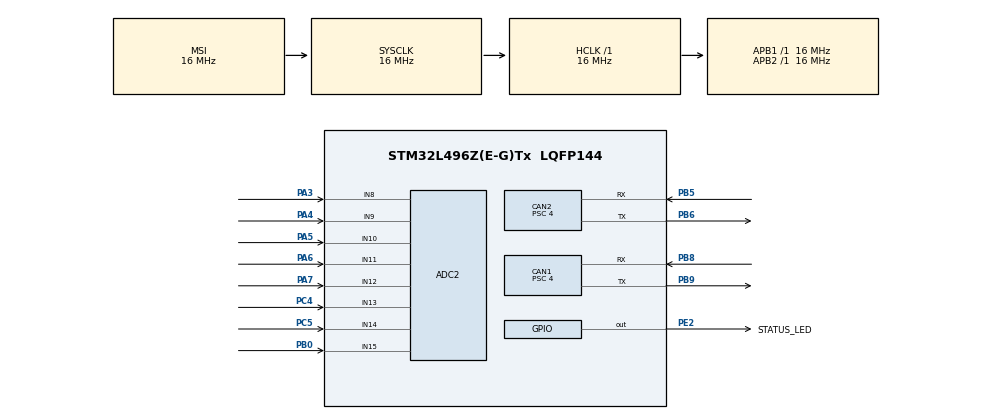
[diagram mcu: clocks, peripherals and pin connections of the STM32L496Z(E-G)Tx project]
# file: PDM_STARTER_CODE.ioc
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ADC2.Channel-1\#ChannelRegularConversion=ADC_CHANNEL_8
ADC2.Channel-2\#ChannelRegularConversion=ADC_CHANNEL_9
ADC2.Channel-3\#ChannelRegularConversion=ADC_CHANNEL_10
ADC2.Channel-4\#ChannelRegularConversion=ADC_CHANNEL_11
ADC2.Channel-5\#ChannelRegularConversion=ADC_CHANNEL_12
ADC2.Channel-6\#ChannelRegularConversion=ADC_CHANNEL_13
ADC2.Channel-7\#ChannelRegularConversion=ADC_CHANNEL_14
ADC2.Channel-8\#ChannelRegularConversion=ADC_CHANNEL_15
ADC2.ClockPrescaler=ADC_CLOCK_ASYNC_DIV1
ADC2.DMAContinuousRequests=ENABLE
ADC2.EOCSelection=ADC_EOC_SEQ_CONV
ADC2.EnableAnalogWatchDog1=false
ADC2.EnableAnalogWatchDog2=false
ADC2.ExternalTrigConv=ADC_EXTERNALTRIG_T8_TRGO
ADC2.NbrOfConversion=8
ADC2.NbrOfConversionFlag=1
ADC2.OffsetNumber-1\#ChannelRegularConversion=ADC_OFFSET_NONE
ADC2.OffsetNumber-2\#ChannelRegularConversion=ADC_OFFSET_NONE
ADC2.OffsetNumber-3\#ChannelRegularConversion=ADC_OFFSET_NONE
ADC2.OffsetNumber-4\#ChannelRegularConversion=ADC_OFFSET_NONE
ADC2.OffsetNumber-5\#ChannelRegularConversion=ADC_OFFSET_NONE
ADC2.OffsetNumber-6\#ChannelRegularConversion=ADC_OFFSET_NONE
ADC2.OffsetNumber-7\#ChannelRegularConversion=ADC_OFFSET_NONE
ADC2.OffsetNumber-8\#ChannelRegularConversion=ADC_OFFSET_NONE
ADC2.Rank-1\#ChannelRegularConversion=1
ADC2.Rank-2\#ChannelRegularConversion=2
ADC2.Rank-3\#ChannelRegularConversion=3
ADC2.Rank-4\#ChannelRegularConversion=4
ADC2.Rank-5\#ChannelRegularConversion=5
ADC2.Rank-6\#ChannelRegularConversion=6
ADC2.Rank-7\#ChannelRegularConversion=7
ADC2.Rank-8\#ChannelRegularConversion=8
ADC2.SamplingTime-1\#ChannelRegularConversion=ADC_SAMPLETIME_12CYCLES_5
ADC2.SamplingTime-2\#ChannelRegularConversion=ADC_SAMPLETIME_12CYCLES_5
ADC2.SamplingTime-3\#ChannelRegularConversion=ADC_SAMPLETIME_12CYCLES_5
ADC2.SamplingTime-4\#ChannelRegularConversion=ADC_SAMPLETIME_12CYCLES_5
ADC2.SamplingTime-5\#ChannelRegularConversion=ADC_SAMPLETIME_12CYCLES_5
ADC2.SamplingTime-6\#ChannelRegularConversion=ADC_SAMPLETIME_12CYCLES_5
ADC2.SamplingTime-7\#ChannelRegularConversion=ADC_SAMPLETIME_12CYCLES_5
ADC2.SamplingTime-8\#ChannelRegularConversion=ADC_SAMPLETIME_12CYCLES_5
CAN1.BS1=CAN_BS1_2TQ
CAN1.CalculateBaudRate=1000000
CAN1.CalculateTimeBit=1000
CAN1.CalculateTimeQuantum=250.0
CAN1.Prescaler=4
CAN2.BS1=CAN_BS1_2TQ
CAN2.CalculateBaudRate=1000000
CAN2.CalculateTimeBit=1000
CAN2.CalculateTimeQuantum=250.0
CAN2.Prescaler=4
Dma.ADC2.0.Direction=DMA_PERIPH_TO_MEMORY
Dma.ADC2.0.Instance=DMA1_Channel2
Dma.ADC2.0.MemDataAlignment=DMA_MDATAALIGN_WORD
Dma.ADC2.0.MemInc=DMA_MINC_ENABLE
Dma.ADC2.0.Mode=DMA_CIRCULAR
Dma.ADC2.0.PeriphDataAlignment=DMA_PDATAALIGN_WORD
Dma.ADC2.0.PeriphInc=DMA_PINC_DISABLE
Dma.ADC2.0.Priority=DMA_PRIORITY_LOW
Dma.Request0=ADC2
FREERTOS.Tasks01=defaultTask,24,128,StartDefaultTask,Default,NULL,Dynamic,NULL,NULL;statusTask,24,128,statusTaskStart,Default,NULL,Dynamic,NULL,NULL;can1Task,24,128,can1TaskStart,As external,NULL,Dynamic,NULL,NULL;can2Task,24,128,can2TaskStart,As external,NULL,Dynamic,NULL,NULL;adcTask,24,128,adcTaskStart,As external,NULL,Dynamic,NULL,NULL
FREERTOS.configENABLE_FPU=0
FREERTOS.configTOTAL_HEAP_SIZE=25360
FREERTOS.configUSE_NEWLIB_REENTRANT=1
Mcu.Family=STM32L4
Mcu.Name=STM32L496Z(E-G)Tx
Mcu.Package=LQFP144
NVIC.DMA1_Channel2_IRQn=true\:5\:0\:false\:false\:true\:true\:false\:true\:true
NVIC.PriorityGroup=NVIC_PRIORITYGROUP_4
NVIC.TIM6_DAC_IRQn=true\:15\:0\:false\:false\:true\:false\:false\:true\:true
NVIC.TimeBase=TIM6_DAC_IRQn
NVIC.TimeBaseIP=TIM6
PA3.Signal=ADCx_IN8
PA4.Signal=ADCx_IN9
PA5.Signal=ADCx_IN10
PA6.Signal=ADCx_IN11
PA7.Signal=ADCx_IN12
PB0.Signal=ADCx_IN15
PB5.Mode=CAN_Activate
PB5.Signal=CAN2_RX
PB6.Mode=CAN_Activate
PB6.Signal=CAN2_TX
PB8.Mode=CAN_Activate
PB8.Signal=CAN1_RX
PB9.Mode=CAN_Activate
PB9.Signal=CAN1_TX
PC4.Signal=ADCx_IN13
PC5.Signal=ADCx_IN14
PC9.Signal=S_TIM3_CH4
PE2.GPIO_Label=STATUS_LED
PE2.Signal=GPIO_Output
ProjectManager.HeapSize=0x200
ProjectManager.StackSize=0x400
ProjectManager.TargetToolchain=STM32CubeIDE
RCC.ADCFreq_Value=64000000
RCC.AHBFreq_Value=16000000
RCC.APB1Freq_Value=16000000
RCC.APB1TimFreq_Value=16000000
RCC.APB2Freq_Value=16000000
RCC.APB2TimFreq_Value=16000000
RCC.CortexFreq_Value=16000000
RCC.HCLKFreq_Value=16000000
RCC.HSE_VALUE=8000000
RCC.HSI48_VALUE=48000000
RCC.HSI_VALUE=16000000
RCC.LSE_VALUE=32768
RCC.MSIClockRange=RCC_MSIRANGE_8
RCC.MSI_VALUE=16000000
RCC.SYSCLKFreq_VALUE=16000000
RCC.USBFreq_Value=64000000
RCC.VCOOutputFreq_Value=128000000
SH.ADCx_IN10.0=ADC2_IN10,IN10-Single-Ended
SH.ADCx_IN11.0=ADC2_IN11,IN11-Single-Ended
SH.ADCx_IN12.0=ADC2_IN12,IN12-Single-Ended
SH.ADCx_IN13.0=ADC2_IN13,IN13-Single-Ended
SH.ADCx_IN14.0=ADC2_IN14,IN14-Single-Ended
SH.ADCx_IN15.0=ADC2_IN15,IN15-Single-Ended
SH.ADCx_IN8.0=ADC2_IN8,IN8-Single-Ended
SH.ADCx_IN9.0=ADC2_IN9,IN9-Single-Ended
SH.S_TIM3_CH4.0=TIM3_CH4
TIM8.Period=49
TIM8.Prescaler=1600-1
TIM8.TIM_MasterOutputTrigger=TIM_TRGO_UPDATE
VP_FREERTOS_VS_CMSIS_V2.Mode=CMSIS_V2
VP_SYS_VS_tim6.Mode=TIM6
VP_TIM8_VS_ClockSourceINT.Mode=Internal
board=custom

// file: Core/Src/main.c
/* USER CODE BEGIN Header */
/**
  ******************************************************************************
  * @file           : main.c
  * @brief          : Main program body
  ******************************************************************************
  * @attention
  *
  * Copyright (c) 2023 STMicroelectronics.
  * All rights reserved.
  *
  * This software is licensed under terms that can be found in the LICENSE file
  * in the root directory of this software component.
  * If no LICENSE file comes with this software, it is provided AS-IS.
  *
  ******************************************************************************
  */
/* USER CODE END Header */
#include "main.h"
#include "cmsis_os.h"
#include "adc.h"
#include "can.h"
#include "dma.h"
#include "tim.h"
#include "gpio.h"

void SystemClock_Config(void);
void MX_FREERTOS_Init(void);

int main(void)
{

  /* MCU Configuration--------------------------------------------------------*/

  /* Reset of all peripherals, Initializes the Flash interface and the Systick. */
  HAL_Init();

  /* Configure the system clock */
  SystemClock_Config();

  /* Initialize all configured peripherals */
  MX_GPIO_Init();
  MX_DMA_Init();
  MX_CAN1_Init();
  MX_CAN2_Init();
  MX_ADC2_Init();
  MX_TIM8_Init();

  /* Init scheduler */
  osKernelInitialize();  /* Call init function for freertos objects (in freertos.c) */
  MX_FREERTOS_Init();

  /* Start scheduler */
  osKernelStart();

  /* We should never get here as control is now taken by the scheduler */
  /* Infinite loop */
  while (1)
  {

  }
}

void SystemClock_Config(void)
{
  RCC_OscInitTypeDef RCC_OscInitStruct = {0};
  RCC_ClkInitTypeDef RCC_ClkInitStruct = {0};

  /** Configure the main internal regulator output voltage
  */
  if (HAL_PWREx_ControlVoltageScaling(PWR_REGULATOR_VOLTAGE_SCALE1) != HAL_OK)
  {
    Error_Handler();
  }

  /** Initializes the RCC Oscillators according to the specified parameters
  * in the RCC_OscInitTypeDef structure.
  */
  RCC_OscInitStruct.OscillatorType = RCC_OSCILLATORTYPE_MSI;
  RCC_OscInitStruct.MSIState = RCC_MSI_ON;
  RCC_OscInitStruct.MSICalibrationValue = 0;
  RCC_OscInitStruct.MSIClockRange = RCC_MSIRANGE_8;
  RCC_OscInitStruct.PLL.PLLState = RCC_PLL_NONE;
  if (HAL_RCC_OscConfig(&RCC_OscInitStruct) != HAL_OK)
  {
    Error_Handler();
  }

  /** Initializes the CPU, AHB and APB buses clocks
  */
  RCC_ClkInitStruct.ClockType = RCC_CLOCKTYPE_HCLK|RCC_CLOCKTYPE_SYSCLK
                              |RCC_CLOCKTYPE_PCLK1|RCC_CLOCKTYPE_PCLK2;
  RCC_ClkInitStruct.SYSCLKSource = RCC_SYSCLKSOURCE_MSI;
  RCC_ClkInitStruct.AHBCLKDivider = RCC_SYSCLK_DIV1;
  RCC_ClkInitStruct.APB1CLKDivider = RCC_HCLK_DIV1;
  RCC_ClkInitStruct.APB2CLKDivider = RCC_HCLK_DIV1;

  if (HAL_RCC_ClockConfig(&RCC_ClkInitStruct, FLASH_LATENCY_0) != HAL_OK)
  {
    Error_Handler();
  }
}

void HAL_TIM_PeriodElapsedCallback(TIM_HandleTypeDef *htim)
{
  if (htim->Instance == TIM6) {
    HAL_IncTick();
  }
}

void Error_Handler(void)
{
  __disable_irq();
  while (1)
  {
  }
}

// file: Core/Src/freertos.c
/* USER CODE BEGIN Header */
/**
  ******************************************************************************
  * File Name          : freertos.c
  * Description        : Code for freertos applications
  ******************************************************************************
  * @attention
  *
  * Copyright (c) 2023 STMicroelectronics.
  * All rights reserved.
  *
  * This software is licensed under terms that can be found in the LICENSE file
  * in the root directory of this software component.
  * If no LICENSE file comes with this software, it is provided AS-IS.
  *
  ******************************************************************************
  */
/* USER CODE END Header */

#include "FreeRTOS.h"
#include "task.h"
#include "main.h"
#include "cmsis_os.h"

/* Definitions for defaultTask */
osThreadId_t defaultTaskHandle;
const osThreadAttr_t defaultTask_attributes = {
  .name = "defaultTask",
  .stack_size = 128 * 4,
  .priority = (osPriority_t) osPriorityNormal,
};
/* Definitions for statusTask */
osThreadId_t statusTaskHandle;
const osThreadAttr_t statusTask_attributes = {
  .name = "statusTask",
  .stack_size = 128 * 4,
  .priority = (osPriority_t) osPriorityNormal,
};
/* Definitions for can1Task */
osThreadId_t can1TaskHandle;
const osThreadAttr_t can1Task_attributes = {
  .name = "can1Task",
  .stack_size = 128 * 4,
  .priority = (osPriority_t) osPriorityNormal,
};
/* Definitions for can2Task */
osThreadId_t can2TaskHandle;
const osThreadAttr_t can2Task_attributes = {
  .name = "can2Task",
  .stack_size = 128 * 4,
  .priority = (osPriority_t) osPriorityNormal,
};
/* Definitions for adcTask */
osThreadId_t adcTaskHandle;
const osThreadAttr_t adcTask_attributes = {
  .name = "adcTask",
  .stack_size = 128 * 4,
  .priority = (osPriority_t) osPriorityNormal,
};

void StartDefaultTask(void *argument);
void statusTaskStart(void *argument);
extern void can1TaskStart(void *argument);
extern void can2TaskStart(void *argument);
extern void adcTaskStart(void *argument);

void MX_FREERTOS_Init(void); /* (MISRA C 2004 rule 8.1) */

void MX_FREERTOS_Init(void) {

  /* Create the thread(s) */
  /* creation of defaultTask */
  defaultTaskHandle = osThreadNew(StartDefaultTask, NULL, &defaultTask_attributes);

  /* creation of statusTask */
  statusTaskHandle = osThreadNew(statusTaskStart, NULL, &statusTask_attributes);

  /* creation of can1Task */
  can1TaskHandle = osThreadNew(can1TaskStart, NULL, &can1Task_attributes);

  /* creation of can2Task */
  can2TaskHandle = osThreadNew(can2TaskStart, NULL, &can2Task_attributes);

  /* creation of adcTask */
  adcTaskHandle = osThreadNew(adcTaskStart, NULL, &adcTask_attributes);

}

void StartDefaultTask(void *argument)
{
  /* USER CODE BEGIN StartDefaultTask */
  /* Infinite loop */
  for(;;)
  {
    osDelay(pdMS_TO_TICKS(100));
  }
  /* USER CODE END StartDefaultTask */
}

void statusTaskStart(void *argument)
{
  /* USER CODE BEGIN statusTaskStart */
  /* Infinite loop */
    for(;;)
    {
        HAL_GPIO_TogglePin(STATUS_LED_GPIO_Port, STATUS_LED_Pin);
        osDelay(500);
    }
  /* USER CODE END statusTaskStart */
}
